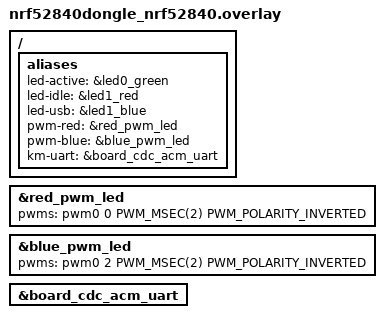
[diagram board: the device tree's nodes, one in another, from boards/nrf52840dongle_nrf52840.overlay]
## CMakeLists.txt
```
cmake_minimum_required(VERSION 3.20.0)
find_package(Zephyr REQUIRED HINTS $ENV{ZEPHYR_BASE})

project(keyboard-switch-ble)

target_sources(app PRIVATE src/main.c)

# Pull in sample_usbd_init_device() used by usb_uart_init()
include(${ZEPHYR_BASE}/samples/subsys/usb/common/common.cmake)
```

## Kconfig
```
# SPDX-License-Identifier: Apache-2.0

mainmenu "KVM Keyboard Switch BLE"

source "$ZEPHYR_BASE/samples/subsys/usb/common/Kconfig.sample_usbd"

source "Kconfig.zephyr"
```

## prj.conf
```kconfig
#
# prj.conf — KVM Dongle (keyboard-only BLE HID peripheral)
#
# SPDX-License-Identifier: Apache-2.0
#

CONFIG_NCS_SAMPLES_DEFAULTS=y
CONFIG_BOARD_SERIAL_BACKEND_CDC_ACM=n

# GPIO (LED + button)
CONFIG_GPIO=y

# PWM (breathing / blink effects on red and blue LEDs)
CONFIG_PWM=y

# Logging disabled — dongle has no physical UART and no J-Link
CONFIG_LOG=n
CONFIG_UART_CONSOLE=n

# Bluetooth
CONFIG_BT=y
CONFIG_BT_PERIPHERAL=y
CONFIG_BT_SMP=y
CONFIG_BT_ATT_TX_COUNT=5

CONFIG_BT_DEVICE_NAME="BLE-KB-Relay"
CONFIG_BT_DEVICE_APPEARANCE=961

CONFIG_BT_GATT_AUTO_SEC_REQ=n
CONFIG_BT_AUTO_PHY_UPDATE=n

# Connection parameters — low latency (7.5ms–15ms → up to 133Hz)
CONFIG_BT_PERIPHERAL_PREF_MIN_INT=6
CONFIG_BT_PERIPHERAL_PREF_MAX_INT=12
CONFIG_BT_PERIPHERAL_PREF_LATENCY=0
CONFIG_BT_PERIPHERAL_PREF_TIMEOUT=100

# Just Works pairing (no PIN), with bonding + Filter Accept List
CONFIG_BT_PRIVACY=y
CONFIG_BT_FILTER_ACCEPT_LIST=y
CONFIG_BT_MAX_CONN=1
CONFIG_BT_MAX_PAIRED=2
# Multiple identities: ID 1 = normal peer, ID 2 = temporary identity for bt_id_reset()
CONFIG_BT_ID_MAX=3

# HIDS (keyboard only, single client)
CONFIG_BT_HIDS=y
CONFIG_BT_HIDS_MAX_CLIENT_COUNT=1
CONFIG_BT_HIDS_DEFAULT_PERM_RW_ENCRYPT=y
CONFIG_BT_GATT_UUID16_POOL_SIZE=40
CONFIG_BT_GATT_CHRC_POOL_SIZE=20
CONFIG_BT_CONN_CTX=y

# Battery Service (required for HID profile)
CONFIG_BT_BAS=y

# Device Information Service
CONFIG_BT_DIS=y
CONFIG_BT_DIS_MANUF_NAME=y
CONFIG_BT_DIS_MANUF_NAME_STR="KBRelay"
CONFIG_BT_DIS_PNP=y
CONFIG_BT_DIS_PNP_VID_SRC=2
CONFIG_BT_DIS_PNP_VID=0x1915
CONFIG_BT_DIS_PNP_PID=0x0004
CONFIG_BT_DIS_PNP_VER=0x0100

# Bond persistence
CONFIG_SETTINGS=y
CONFIG_BT_SETTINGS=y
CONFIG_FLASH=y
CONFIG_FLASH_PAGE_LAYOUT=y
CONFIG_FLASH_MAP=y
CONFIG_NVS=y

# USB CDC-ACM (new USBD stack)
CONFIG_USB_DEVICE_STACK_NEXT=y
CONFIG_SERIAL=y
CONFIG_USBD_CDC_ACM_CLASS=y
CONFIG_UART_LINE_CTRL=y
CONFIG_UART_INTERRUPT_DRIVEN=y
CONFIG_HWINFO=y
CONFIG_SAMPLE_USBD_MANUFACTURER="KBRelay"
CONFIG_SAMPLE_USBD_PRODUCT="BLE KB Relay"
CONFIG_SAMPLE_USBD_PID=0x0004

# Stack sizes
CONFIG_MAIN_STACK_SIZE=4096
CONFIG_SYSTEM_WORKQUEUE_STACK_SIZE=2048
CONFIG_HEAP_MEM_POOL_SIZE=8192
```

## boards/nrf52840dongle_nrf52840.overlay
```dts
/*
 * boards/nrf52840dongle_nrf52840.overlay
 *
 * LED aliases (GPIO + PWM) + USB CDC ACM alias for km_proto frame reception.
 *
 * Board node labels (from nrf52840dongle_nrf52840_common.dtsi):
 *   led0_green : P0.06  ACTIVE_LOW  (GPIO only)
 *   led1_red   : P0.08  ACTIVE_LOW  (PWM0 ch0)
 *   led1_green : P1.09  ACTIVE_LOW  (PWM0 ch1)
 *   led1_blue  : P0.12  ACTIVE_LOW  (PWM0 ch2)
 */

/ {
	aliases {
		led-active  = &led0_green;   /* green GPIO — connected state  */
		led-idle    = &led1_red;     /* red  GPIO  — fallback         */
		led-usb     = &led1_blue;    /* blue GPIO  — fallback         */
		pwm-red     = &red_pwm_led;  /* red  PWM   — breathing        */
		pwm-blue    = &blue_pwm_led; /* blue PWM   — adv blink        */
	};
};

/* Board defines PWM LEDs as ACTIVE_LOW (PWM_POLARITY_INVERTED).
 * Override to POLARITY_NORMAL: pulse=0 → off, pulse=period → full brightness. */
&red_pwm_led {
	pwms = <&pwm0 0 PWM_MSEC(2) PWM_POLARITY_INVERTED>;
};

&blue_pwm_led {
	pwms = <&pwm0 2 PWM_MSEC(2) PWM_POLARITY_INVERTED>;
};

/* Enable the board's built-in CDC ACM UART and use it as the km serial port */
&board_cdc_acm_uart {
	status = "okay";
};

/ {
	aliases {
		km-uart = &board_cdc_acm_uart;
	};
};
```

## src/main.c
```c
/*
 * src/main.c — KVM Dongle firmware (keyboard-only)
 *
 * Advertising strategy:
 *   - ID 1 (peer identity), has bonds → undirected adv + FAL (FILTER_CONN + FILTER_SCAN_REQ)
 *     Windows RPA is resolved by the controller via the Resolving List (IRK added during
 *     bonding), so FAL + FILTER_CONN works correctly for bonded Windows peers.
 *   - ID 1, no bonds, pairing_mode=false → idle, red slow breathe, wait for SW1
 *   - ID 1, no bonds, pairing_mode=true  → open undirected adv (SW1 long-press)
 *
 * Stale LTK handling (Windows reconnect after firmware reset):
 *   When PIN_OR_KEY_MISSING fires, reset ID 1 via bt_id_reset() so Windows sees a
 *   brand-new device and initiates fresh pairing without manual bond deletion.
 *
 * Identity map (CONFIG_BT_ID_MAX=3):
 *   ID 0 (BT_ID_DEFAULT) — unused (reserved, nRF Desktop convention)
 *   ID 1 (PEER_ID)       — normal peer / bonding identity
 *   ID 2 (TEMP_ID)       — temporary identity used during bt_id_reset() swap
 *
 * LED states:
 *   red breathing        = initializing / no bond, waiting for SW1
 *   blue fast blink      = advertising
 *   purple blink (200ms) = connected, waiting for security
 *   green solid          = secured / connected
 *   green 30ms flash     = HID report sent
 *
 * Serial frame format: [0xAA][TYPE:1B][LEN:1B][PAYLOAD:LEN B][CRC8-CCITT:1B]
 *   TYPE 0x01 → keyboard report  (8 B: mods, reserved, 6 keycodes)
 *   TYPE 0x03 → all-keys-release (8 B payload ignored, sends zero report)
 *
 * SPDX-License-Identifier: Apache-2.0
 */

#include <zephyr/kernel.h>
#include <zephyr/device.h>
#include <zephyr/devicetree.h>
#include <zephyr/drivers/gpio.h>
#include <zephyr/drivers/pwm.h>
#include <zephyr/drivers/uart.h>
#include <zephyr/logging/log.h>
#include <zephyr/settings/settings.h>
#include <zephyr/sys/ring_buffer.h>
#include <zephyr/sys/crc.h>
#include <zephyr/usb/usbd.h>
#include <sample_usbd.h>

#include <zephyr/bluetooth/bluetooth.h>
#include <zephyr/bluetooth/hci.h>
#include <zephyr/bluetooth/conn.h>
#include <zephyr/bluetooth/uuid.h>
#include <zephyr/bluetooth/gatt.h>
#include <zephyr/bluetooth/services/bas.h>
#include <bluetooth/services/hids.h>

LOG_MODULE_REGISTER(kvm_dongle, LOG_LEVEL_INF);

/* ── Identity indices ────────────────────────────────────────────────── */
#define PEER_ID  1
#define TEMP_ID  2

/* ── HID keyboard payload ────────────────────────────────────────────── */
typedef struct {
	uint8_t mods;
	uint8_t reserved;
	uint8_t keys[6];
} payload_kb_t;

/* ── GPIO ────────────────────────────────────────────────────────────── */
static const struct gpio_dt_spec led_active = GPIO_DT_SPEC_GET(DT_ALIAS(led_active), gpios);
static const struct gpio_dt_spec btn        = GPIO_DT_SPEC_GET(DT_ALIAS(sw0),        gpios);

/* ── PWM ─────────────────────────────────────────────────────────────── */
static const struct pwm_dt_spec pwm_red  = PWM_DT_SPEC_GET(DT_ALIAS(pwm_red));
static const struct pwm_dt_spec pwm_blue = PWM_DT_SPEC_GET(DT_ALIAS(pwm_blue));

#define PWM_PERIOD_US  2000U
#define PWM_PERIOD     PWM_USEC(PWM_PERIOD_US)

/* ── LED effect engine ───────────────────────────────────────────────── */
typedef enum {
	EFFECT_OFF,
	EFFECT_GREEN_ON,
	EFFECT_RED_BREATHE,
	EFFECT_BLUE_BLINK,
	EFFECT_PURPLE_BLINK,
} led_effect_t;

static atomic_t current_effect = ATOMIC_INIT(EFFECT_OFF);
static struct k_timer led_timer;
static struct k_work  led_work;
static uint32_t led_tick;

static uint8_t breathe_lut(uint32_t tick)
{
	uint32_t phase = tick & 127U;

	return (phase < 64U) ? (uint8_t)(phase * 4U)
			     : (uint8_t)((127U - phase) * 4U);
}

static void led_work_handler(struct k_work *work)
{
	led_effect_t eff = (led_effect_t)atomic_get(&current_effect);

	led_tick++;

	switch (eff) {
	case EFFECT_OFF:
		pwm_set_dt(&pwm_red,  PWM_PERIOD, 0);
		pwm_set_dt(&pwm_blue, PWM_PERIOD, 0);
		gpio_pin_set_dt(&led_active, 0);
		break;

	case EFFECT_GREEN_ON:
		pwm_set_dt(&pwm_red,  PWM_PERIOD, 0);
		pwm_set_dt(&pwm_blue, PWM_PERIOD, 0);
		gpio_pin_set_dt(&led_active, 1);
		break;

	case EFFECT_RED_BREATHE: {
		uint32_t bright = breathe_lut(led_tick);
		uint32_t pulse  = (PWM_PERIOD * bright) / 255U;

		pwm_set_dt(&pwm_red,  PWM_PERIOD, pulse);
		pwm_set_dt(&pwm_blue, PWM_PERIOD, 0);
		gpio_pin_set_dt(&led_active, 0);
		break;
	}

	case EFFECT_BLUE_BLINK: {
		uint32_t pulse = ((led_tick % 12U) < 6U) ? PWM_PERIOD : 0U;

		pwm_set_dt(&pwm_red,  PWM_PERIOD, 0);
		pwm_set_dt(&pwm_blue, PWM_PERIOD, pulse);
		gpio_pin_set_dt(&led_active, 0);
		break;
	}

	case EFFECT_PURPLE_BLINK: {
		uint32_t pulse = ((led_tick % 10U) < 5U) ? PWM_PERIOD : 0U;

		pwm_set_dt(&pwm_red,  PWM_PERIOD, pulse);
		pwm_set_dt(&pwm_blue, PWM_PERIOD, pulse);
		gpio_pin_set_dt(&led_active, 0);
		break;
	}
	}
}

static void led_timer_cb(struct k_timer *t)
{
	k_work_submit(&led_work);
}

static void led_set_effect(led_effect_t eff)
{
	led_tick = 0;
	atomic_set(&current_effect, (atomic_val_t)eff);
}

static void led_set_advertising(void) { led_set_effect(EFFECT_BLUE_BLINK);   }
static void led_set_connected(void)   { led_set_effect(EFFECT_GREEN_ON);     }
static void led_set_securing(void)    { led_set_effect(EFFECT_PURPLE_BLINK); }
static void led_set_idle(void)        { led_set_effect(EFFECT_RED_BREATHE);  }

/* ── HID TX indicator ────────────────────────────────────────────────── */
static struct k_work_delayable hid_tx_work;

static void hid_tx_work_handler(struct k_work *work)
{
	if ((led_effect_t)atomic_get(&current_effect) == EFFECT_GREEN_ON) {
		gpio_pin_set_dt(&led_active, 1);
	}
}

static void hid_tx_flash(void)
{
	if ((led_effect_t)atomic_get(&current_effect) != EFFECT_GREEN_ON) {
		return;
	}
	gpio_pin_set_dt(&led_active, 0);
	k_work_reschedule(&hid_tx_work, K_MSEC(30));
}

/* ── Button interrupt ────────────────────────────────────────────────── */
static struct gpio_callback btn_cb_data;
static struct k_work_delayable btn_work;

static void btn_work_handler(struct k_work *work);  /* forward declaration */

static void btn_isr(const struct device *dev, struct gpio_callback *cb, uint32_t pins)
{
	bool pressed = (gpio_pin_get_dt(&btn) == 1);

	if (pressed) {
		k_work_reschedule(&btn_work, K_MSEC(3000));
	} else {
		k_work_cancel_delayable(&btn_work);
	}
}

/* ── BLE state ───────────────────────────────────────────────────────── */
static struct bt_conn *current_conn;
static bool pairing_mode;

/* ── Advertising data ────────────────────────────────────────────────── */
static const struct bt_data ad[] = {
	BT_DATA_BYTES(BT_DATA_FLAGS, BT_LE_AD_GENERAL | BT_LE_AD_NO_BREDR),
	BT_DATA_BYTES(BT_DATA_UUID16_ALL,
		      BT_UUID_16_ENCODE(BT_UUID_HIDS_VAL),
		      BT_UUID_16_ENCODE(BT_UUID_BAS_VAL)),
};

static const struct bt_data sd[] = {
	BT_DATA(BT_DATA_NAME_COMPLETE,
		CONFIG_BT_DEVICE_NAME,
		sizeof(CONFIG_BT_DEVICE_NAME) - 1),
};

/* ── Filter Accept List ──────────────────────────────────────────────── */
static void accept_list_add(const struct bt_bond_info *info, void *user_data)
{
	int *cnt = user_data;
	int err  = bt_le_filter_accept_list_add(&info->addr);

	if (err) {
		LOG_WRN("accept_list_add failed: %d", err);
	} else {
		(*cnt)++;
	}
}

/* ── Advertising work ────────────────────────────────────────────────── */
static struct k_work adv_work;

static void adv_work_handler(struct k_work *work)
{
	struct bt_le_adv_param adv_param = {
		.id           = PEER_ID,
		.options      = BT_LE_ADV_OPT_CONN,
		.interval_min = BT_GAP_ADV_FAST_INT_MIN_2,
		.interval_max = BT_GAP_ADV_FAST_INT_MAX_2,
	};
	int err;

	bt_le_filter_accept_list_clear();

	if (!pairing_mode) {
		int bond_cnt = 0;

		bt_foreach_bond(PEER_ID, accept_list_add, &bond_cnt);

		if (bond_cnt == 0) {
			LOG_INF("No bonds — long-press SW1 to pair");
			led_set_idle();
			return;
		}

		adv_param.options |= BT_LE_ADV_OPT_FILTER_SCAN_REQ;
		adv_param.options |= BT_LE_ADV_OPT_FILTER_CONN;
		LOG_INF("Advertising (bonded-only, %d peer(s))", bond_cnt);
	} else {
		LOG_INF("Advertising open (pairing mode)");
	}

	err = bt_le_adv_start(&adv_param, ad, ARRAY_SIZE(ad), sd, ARRAY_SIZE(sd));
	if (err && err != -EALREADY) {
		LOG_ERR("bt_le_adv_start failed: %d", err);
		return;
	}
	led_set_advertising();
}

static void advertising_start(void)
{
	bt_le_adv_stop();
	k_work_submit(&adv_work);
}

/* ── Identity reset work ─────────────────────────────────────────────── */
static struct k_work identity_reset_work;

static void identity_reset_handler(struct k_work *work)
{
	int err = bt_id_reset(PEER_ID, NULL, NULL);

	if (err < 0) {
		LOG_ERR("bt_id_reset failed: %d", err);
	} else {
		LOG_INF("Identity reset — new address assigned to ID %d", PEER_ID);
	}

	pairing_mode = true;
	advertising_start();
}

/* ── SW1 long-press handler ──────────────────────────────────────────── */
static void btn_work_handler(struct k_work *work)
{
	if (gpio_pin_get_dt(&btn) != 1) {
		return;
	}

	LOG_INF("Long press — resetting identity, entering pairing mode");

	if (current_conn) {
		pairing_mode = true;
		bt_conn_disconnect(current_conn, BT_HCI_ERR_REMOTE_USER_TERM_CONN);
	} else {
		k_work_submit(&identity_reset_work);
	}
}

/* ═══════════════════════════════════════════════════════════════════════
 * HID Report Descriptor — keyboard only (Report ID 1)
 * ═══════════════════════════════════════════════════════════════════════ */
static const uint8_t hid_report_desc[] = {
	/* Keyboard — Report ID 1 */
	0x05, 0x01, 0x09, 0x06, 0xA1, 0x01, 0x85, 0x01,
	/* Modifier keys */
	0x05, 0x07, 0x19, 0xE0, 0x29, 0xE7,
	0x15, 0x00, 0x25, 0x01, 0x75, 0x01, 0x95, 0x08, 0x81, 0x02,
	/* Reserved byte */
	0x95, 0x01, 0x75, 0x08, 0x81, 0x01,
	/* Keycodes (6-key rollover) */
	0x95, 0x06, 0x75, 0x08, 0x15, 0x00, 0x25, 0x65,
	0x05, 0x07, 0x19, 0x00, 0x29, 0x65, 0x81, 0x00,
	/* LED output report (NumLock, CapsLock, ScrollLock, Compose, Kana) */
	0x05, 0x08, 0x19, 0x01, 0x29, 0x05,
	0x95, 0x05, 0x75, 0x01, 0x91, 0x02,
	0x95, 0x01, 0x75, 0x03, 0x91, 0x01,
	0xC0,
};

#define REP_IDX_KB  0

BT_HIDS_DEF(hids_obj, sizeof(payload_kb_t), 1);

static void hids_led_handler(struct bt_hids_rep *rep,
			     struct bt_conn *conn, bool is_write)
{
	if (is_write && rep->data && rep->size >= 1) {
		LOG_DBG("LED state: 0x%02x", rep->data[0]);
	}
}

static int hids_init(void)
{
	struct bt_hids_init_param p = {0};

	p.inp_rep_group_init.reports[REP_IDX_KB].size = sizeof(payload_kb_t);
	p.inp_rep_group_init.reports[REP_IDX_KB].id   = 1;
	p.inp_rep_group_init.cnt = 1;

	p.outp_rep_group_init.reports[0].size    = 1;
	p.outp_rep_group_init.reports[0].id      = 1;
	p.outp_rep_group_init.reports[0].handler = hids_led_handler;
	p.outp_rep_group_init.cnt = 1;

	p.rep_map.data = hid_report_desc;
	p.rep_map.size = sizeof(hid_report_desc);

	p.info.bcd_hid        = 0x0111;
	p.info.b_country_code = 0x00;
	p.info.flags = BT_HIDS_REMOTE_WAKE | BT_HIDS_NORMALLY_CONNECTABLE;
	p.is_kb    = true;
	p.is_mouse = false;
	p.boot_kb_outp_rep_handler = hids_led_handler;

	return bt_hids_init(&hids_obj, &p);
}

/* ═══════════════════════════════════════════════════════════════════════
 * USB CDC-ACM + km_proto frame receiver
 *
 * Frame: [0xAA][TYPE:1B][LEN:1B][PAYLOAD:LEN B][CRC8-CCITT:1B]
 *   TYPE 0x01 → keyboard report  (8 B)
 *   TYPE 0x03 → all-keys-release (payload ignored, sends zero report)
 * ═══════════════════════════════════════════════════════════════════════ */
#define KM_FRAME_MAGIC   0xAAU
#define KM_TYPE_KB       0x01U
#define KM_TYPE_RELEASE  0x03U
#define KM_PAYLOAD_MAX   16U
#define KM_CRC_INIT      0xFFU

static const struct device *km_uart = DEVICE_DT_GET(DT_ALIAS(km_uart));
static struct usbd_context  *usbd_ctx;

RING_BUF_DECLARE(uart_rx_rb, 256);
static struct k_work uart_rx_work;

static void frame_dispatch(uint8_t type, const uint8_t *p, uint8_t len)
{
	static const uint8_t zero_report[sizeof(payload_kb_t)] = {0};

	if (!current_conn) {
		return;
	}

	if (type == KM_TYPE_RELEASE) {
		bt_hids_inp_rep_send(&hids_obj, current_conn,
				     REP_IDX_KB, zero_report,
				     sizeof(zero_report), NULL);
		return;
	}

	if (type == KM_TYPE_KB && len == sizeof(payload_kb_t)) {
		bt_hids_inp_rep_send(&hids_obj, current_conn,
				     REP_IDX_KB, p, len, NULL);
		hid_tx_flash();
	} else {
		LOG_WRN("frame_dispatch: unknown type=0x%02x len=%u", type, len);
	}
}

typedef enum {
	ST_MAGIC,
	ST_TYPE,
	ST_LEN,
	ST_PAYLOAD,
	ST_CRC,
} frame_state_t;

static void uart_rx_work_handler(struct k_work *work)
{
	static frame_state_t state = ST_MAGIC;
	static uint8_t       f_type;
	static uint8_t       f_len;
	static uint8_t       f_buf[KM_PAYLOAD_MAX];
	static uint8_t       f_idx;

	uint8_t byte;

	while (ring_buf_get(&uart_rx_rb, &byte, 1) == 1) {
		switch (state) {
		case ST_MAGIC:
			if (byte == KM_FRAME_MAGIC) {
				state = ST_TYPE;
			}
			break;

		case ST_TYPE:
			f_type = byte;
			state  = ST_LEN;
			break;

		case ST_LEN:
			if (byte == 0 || byte > KM_PAYLOAD_MAX) {
				LOG_WRN("Bad frame len: %u — resync", byte);
				state = ST_MAGIC;
				break;
			}
			f_len = byte;
			f_idx = 0;
			state = ST_PAYLOAD;
			break;

		case ST_PAYLOAD:
			f_buf[f_idx++] = byte;
			if (f_idx == f_len) {
				state = ST_CRC;
			}
			break;

		case ST_CRC: {
			uint8_t crc = crc8_ccitt(KM_CRC_INIT, f_buf, f_len);

			if (crc == byte) {
				frame_dispatch(f_type, f_buf, f_len);
			} else {
				LOG_WRN("CRC mismatch: got 0x%02x expect 0x%02x",
					byte, crc);
			}
			state = ST_MAGIC;
			break;
		}
		}
	}
}

static void uart_isr(const struct device *dev, void *user_data)
{
	ARG_UNUSED(user_data);

	while (uart_irq_update(dev) && uart_irq_is_pending(dev)) {
		if (!uart_irq_rx_ready(dev)) {
			break;
		}

		uint8_t buf[64];
		int     n = uart_fifo_read(dev, buf, sizeof(buf));

		if (n > 0) {
			uint32_t written = ring_buf_put(&uart_rx_rb, buf, n);

			if (written < (uint32_t)n) {
				LOG_WRN("uart_rx_rb full, dropped %d B", n - (int)written);
			}
			k_work_submit(&uart_rx_work);
		}
	}
}

static void usbd_msg_cb(struct usbd_context *const ctx, const struct usbd_msg *msg)
{
	LOG_DBG("USBD: %s", usbd_msg_type_string(msg->type));

	if (usbd_can_detect_vbus(ctx)) {
		if (msg->type == USBD_MSG_VBUS_READY) {
			if (usbd_enable(ctx)) {
				LOG_ERR("usbd_enable failed");
			}
		} else if (msg->type == USBD_MSG_VBUS_REMOVED) {
			usbd_disable(ctx);
		}
	}
}

static int usb_uart_init(void)
{
	int err;

	if (!device_is_ready(km_uart)) {
		LOG_ERR("CDC ACM UART not ready");
		return -ENODEV;
	}

	usbd_ctx = sample_usbd_init_device(usbd_msg_cb);
	if (!usbd_ctx) {
		LOG_ERR("sample_usbd_init_device failed");
		return -ENODEV;
	}

	if (!usbd_can_detect_vbus(usbd_ctx)) {
		err = usbd_enable(usbd_ctx);
		if (err) {
			LOG_ERR("usbd_enable failed: %d", err);
			return err;
		}
	}

	k_work_init(&uart_rx_work, uart_rx_work_handler);
	uart_irq_callback_user_data_set(km_uart, uart_isr, NULL);
	uart_irq_rx_enable(km_uart);

	LOG_INF("USB CDC-ACM ready");
	return 0;
}

/* ═══════════════════════════════════════════════════════════════════════
 * BLE connection callbacks
 * ═══════════════════════════════════════════════════════════════════════ */
static void connected(struct bt_conn *conn, uint8_t err)
{
	if (err) {
		LOG_ERR("Connection failed: 0x%02x", err);
		advertising_start();
		return;
	}
	current_conn = bt_conn_ref(conn);
	bt_hids_connected(&hids_obj, conn);
	led_set_securing();
	LOG_INF("Connected");
}

static void disconnected(struct bt_conn *conn, uint8_t reason)
{
	LOG_INF("Disconnected (0x%02x)", reason);
	bt_hids_disconnected(&hids_obj, conn);
	bt_conn_unref(current_conn);
	current_conn = NULL;

	k_work_cancel_delayable(&hid_tx_work);

	if (pairing_mode) {
		k_work_submit(&identity_reset_work);
	} else {
		advertising_start();
	}
}

static void security_changed(struct bt_conn *conn, bt_security_t level,
			      enum bt_security_err err)
{
	if (err == BT_SECURITY_ERR_PIN_OR_KEY_MISSING) {
		LOG_WRN("Stale LTK — resetting identity for automatic re-pair");
		pairing_mode = true;
		bt_conn_disconnect(conn, BT_HCI_ERR_AUTH_FAIL);
		return;
	}
	if (err) {
		LOG_WRN("Security failed (%d) — disconnecting", err);
		bt_conn_disconnect(conn, BT_HCI_ERR_AUTH_FAIL);
		return;
	}
	if (level >= BT_SECURITY_L2) {
		LOG_INF("Secured (level %d)", level);
		led_set_connected();
	}
}

BT_CONN_CB_DEFINE(conn_cb) = {
	.connected        = connected,
	.disconnected     = disconnected,
	.security_changed = security_changed,
};

static void pairing_complete(struct bt_conn *conn, bool bonded)
{
	LOG_INF("Paired (bonded=%d)", bonded);
	pairing_mode = false;
}

static void pairing_failed(struct bt_conn *conn, enum bt_security_err reason)
{
	LOG_WRN("Pairing failed (%d)", reason);
	bt_conn_disconnect(conn, BT_HCI_ERR_AUTH_FAIL);
}

static struct bt_conn_auth_info_cb auth_info_cb = {
	.pairing_complete = pairing_complete,
	.pairing_failed   = pairing_failed,
};

/* ═══════════════════════════════════════════════════════════════════════
 * main
 * ═══════════════════════════════════════════════════════════════════════ */
int main(void)
{
	int err;

	gpio_pin_configure_dt(&led_active, GPIO_OUTPUT_INACTIVE);

	gpio_pin_configure_dt(&btn, GPIO_INPUT);
	gpio_pin_interrupt_configure_dt(&btn, GPIO_INT_EDGE_BOTH);
	gpio_init_callback(&btn_cb_data, btn_isr, BIT(btn.pin));
	gpio_add_callback(btn.port, &btn_cb_data);

	k_work_init(&led_work, led_work_handler);
	k_timer_init(&led_timer, led_timer_cb, NULL);
	k_timer_start(&led_timer, K_MSEC(20), K_MSEC(20));

	k_work_init_delayable(&hid_tx_work, hid_tx_work_handler);
	k_work_init_delayable(&btn_work, btn_work_handler);

	k_work_init(&adv_work,            adv_work_handler);
	k_work_init(&identity_reset_work, identity_reset_handler);

	err = usb_uart_init();
	if (err) {
		LOG_ERR("usb_uart_init: %d", err);
		return err;
	}

	led_set_idle();
	err = bt_enable(NULL);
	if (err) {
		LOG_ERR("bt_enable: %d", err);
		return err;
	}

	settings_load();

	size_t id_count = 0;

	bt_id_get(NULL, &id_count);
	for (size_t i = id_count; i <= TEMP_ID; i++) {
		err = bt_id_create(NULL, NULL);
		if (err < 0) {
			LOG_ERR("bt_id_create failed: %d", err);
			break;
		}
		LOG_INF("Created BT identity ID %d", err);
	}

	bt_unpair(TEMP_ID, BT_ADDR_LE_ANY);

	bt_conn_auth_cb_register(NULL);
	bt_conn_auth_info_cb_register(&auth_info_cb);

	err = hids_init();
	if (err) {
		LOG_ERR("hids_init: %d", err);
		return err;
	}

	advertising_start();

	return 0;
}
```
